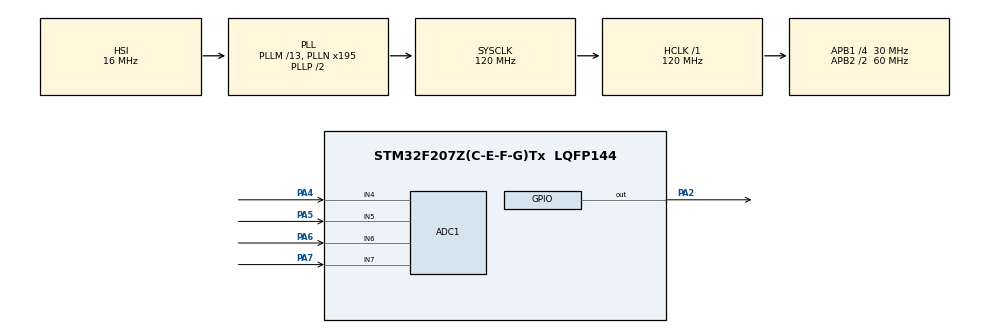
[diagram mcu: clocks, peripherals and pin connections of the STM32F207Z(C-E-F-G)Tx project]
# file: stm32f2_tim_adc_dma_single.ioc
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ADC1.Channel-0\#ChannelRegularConversion=ADC_CHANNEL_4
ADC1.Channel-1\#ChannelRegularConversion=ADC_CHANNEL_5
ADC1.Channel-2\#ChannelRegularConversion=ADC_CHANNEL_6
ADC1.Channel-3\#ChannelRegularConversion=ADC_CHANNEL_7
ADC1.DMAContinuousRequests=ENABLE
ADC1.ExternalTrigConv=ADC_EXTERNALTRIGCONV_T2_TRGO
ADC1.NbrOfConversion=4
ADC1.NbrOfConversionFlag=1
ADC1.Rank-0\#ChannelRegularConversion=1
ADC1.Rank-1\#ChannelRegularConversion=2
ADC1.Rank-2\#ChannelRegularConversion=3
ADC1.Rank-3\#ChannelRegularConversion=4
ADC1.SamplingTime-0\#ChannelRegularConversion=ADC_SAMPLETIME_3CYCLES
ADC1.SamplingTime-1\#ChannelRegularConversion=ADC_SAMPLETIME_3CYCLES
ADC1.SamplingTime-2\#ChannelRegularConversion=ADC_SAMPLETIME_3CYCLES
ADC1.SamplingTime-3\#ChannelRegularConversion=ADC_SAMPLETIME_3CYCLES
ADC1.master=1
Dma.ADC1.0.Direction=DMA_PERIPH_TO_MEMORY
Dma.ADC1.0.FIFOMode=DMA_FIFOMODE_DISABLE
Dma.ADC1.0.Instance=DMA2_Stream0
Dma.ADC1.0.MemDataAlignment=DMA_MDATAALIGN_HALFWORD
Dma.ADC1.0.MemInc=DMA_MINC_ENABLE
Dma.ADC1.0.Mode=DMA_CIRCULAR
Dma.ADC1.0.PeriphDataAlignment=DMA_PDATAALIGN_HALFWORD
Dma.ADC1.0.PeriphInc=DMA_PINC_DISABLE
Dma.ADC1.0.Priority=DMA_PRIORITY_LOW
Dma.Request0=ADC1
Mcu.Family=STM32F2
Mcu.Name=STM32F207Z(C-E-F-G)Tx
Mcu.Package=LQFP144
NVIC.ADC_IRQn=true\:0\:0\:false\:false\:true\:true\:true\:true
NVIC.DMA2_Stream0_IRQn=true\:0\:0\:false\:false\:true\:false\:true\:true
NVIC.PriorityGroup=NVIC_PRIORITYGROUP_4
NVIC.TIM2_IRQn=true\:0\:0\:false\:false\:true\:true\:true\:true
NVIC.TIM3_IRQn=true\:0\:0\:false\:false\:true\:true\:true\:true
PA13.Mode=Serial_Wire
PA13.Signal=SYS_JTMS-SWDIO
PA14.Mode=Serial_Wire
PA14.Signal=SYS_JTCK-SWCLK
PA2.Signal=GPIO_Output
PA4.Signal=ADCx_IN4
PA5.Signal=ADCx_IN5
PA6.Signal=ADCx_IN6
PA7.Signal=ADCx_IN7
PH0-OSC_IN.Mode=HSE-External-Oscillator
PH0-OSC_IN.Signal=RCC_OSC_IN
PH1-OSC_OUT.Mode=HSE-External-Oscillator
PH1-OSC_OUT.Signal=RCC_OSC_OUT
ProjectManager.HeapSize=0x200
ProjectManager.StackSize=0x400
ProjectManager.TargetToolchain=STM32CubeIDE
RCC.48MHZClocksFreq_Value=60000000
RCC.AHBFreq_Value=120000000
RCC.APB1CLKDivider=RCC_HCLK_DIV4
RCC.APB1Freq_Value=30000000
RCC.APB1TimFreq_Value=60000000
RCC.APB2CLKDivider=RCC_HCLK_DIV2
RCC.APB2Freq_Value=60000000
RCC.APB2TimFreq_Value=120000000
RCC.CortexFreq_Value=120000000
RCC.HCLKFreq_Value=120000000
RCC.HSE_VALUE=25000000
RCC.HSI_VALUE=16000000
RCC.LSE_VALUE=32768
RCC.PLLM=13
RCC.PLLN=195
RCC.SYSCLKFreq_VALUE=120000000
RCC.SYSCLKSource=RCC_SYSCLKSOURCE_PLLCLK
RCC.VCOOutputFreq_Value=240000000
SH.ADCx_IN4.0=ADC1_IN4,IN4
SH.ADCx_IN5.0=ADC1_IN5,IN5
SH.ADCx_IN6.0=ADC1_IN6,IN6
SH.ADCx_IN7.0=ADC1_IN7,IN7
TIM2.Channel-PWM\ Generation1\ No\ Output=TIM_CHANNEL_1
TIM2.Period=200-1
TIM2.TIM_MasterOutputTrigger=TIM_TRGO_UPDATE
TIM2.TIM_MasterSlaveMode=TIM_MASTERSLAVEMODE_ENABLE
TIM3.Period=200-1
VP_TIM2_VS_ClockSourceINT.Mode=Internal
VP_TIM2_VS_no_output1.Mode=PWM Generation1 No Output
VP_TIM3_VS_ClockSourceINT.Mode=Internal
board=custom

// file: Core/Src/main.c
/* USER CODE BEGIN Header */
/**
  ******************************************************************************
  * @file           : main.c
  * @brief          : Main program body
  ******************************************************************************
  * @attention
  *
  * Copyright (c) 2023 STMicroelectronics.
  * All rights reserved.
  *
  * This software is licensed under terms that can be found in the LICENSE file
  * in the root directory of this software component.
  * If no LICENSE file comes with this software, it is provided AS-IS.
  *
  ******************************************************************************
  */
/* USER CODE END Header */
#include "main.h"

ADC_HandleTypeDef hadc1;
DMA_HandleTypeDef hdma_adc1;

TIM_HandleTypeDef htim2;
TIM_HandleTypeDef htim3;

/* USER CODE BEGIN PV */
uint16_t adc_values[4];
float Vout[4];
/* USER CODE END PV */

void SystemClock_Config(void);
static void MX_GPIO_Init(void);
static void MX_DMA_Init(void);
static void MX_ADC1_Init(void);
static void MX_TIM2_Init(void);
static void MX_TIM3_Init(void);

int main(void)
{

  /* MCU Configuration--------------------------------------------------------*/

  /* Reset of all peripherals, Initializes the Flash interface and the Systick. */
  HAL_Init();

  /* Configure the system clock */
  SystemClock_Config();

  /* Initialize all configured peripherals */
  MX_GPIO_Init();
  MX_DMA_Init();
  MX_ADC1_Init();
  MX_TIM2_Init();
  MX_TIM3_Init();
  /* USER CODE BEGIN 2 */
  HAL_ADC_Start_DMA(&hadc1, &adc_values, 4);
//  HAL_TIM_Base_Start(&htim2);
//  HAL_TIM_Base_Start_IT(&htim3);
  HAL_TIM_Base_Start(&htim2);

  /* USER CODE END 2 */

  /* Infinite loop */
  while (1)
  {

  }
}

void SystemClock_Config(void)
{
  RCC_OscInitTypeDef RCC_OscInitStruct = {0};
  RCC_ClkInitTypeDef RCC_ClkInitStruct = {0};

  /** Initializes the RCC Oscillators according to the specified parameters
  * in the RCC_OscInitTypeDef structure.
  */
  RCC_OscInitStruct.OscillatorType = RCC_OSCILLATORTYPE_HSI;
  RCC_OscInitStruct.HSIState = RCC_HSI_ON;
  RCC_OscInitStruct.HSICalibrationValue = RCC_HSICALIBRATION_DEFAULT;
  RCC_OscInitStruct.PLL.PLLState = RCC_PLL_ON;
  RCC_OscInitStruct.PLL.PLLSource = RCC_PLLSOURCE_HSI;
  RCC_OscInitStruct.PLL.PLLM = 13;
  RCC_OscInitStruct.PLL.PLLN = 195;
  RCC_OscInitStruct.PLL.PLLP = RCC_PLLP_DIV2;
  RCC_OscInitStruct.PLL.PLLQ = 4;
  if (HAL_RCC_OscConfig(&RCC_OscInitStruct) != HAL_OK)
  {
    Error_Handler();
  }

  /** Initializes the CPU, AHB and APB buses clocks
  */
  RCC_ClkInitStruct.ClockType = RCC_CLOCKTYPE_HCLK|RCC_CLOCKTYPE_SYSCLK
                              |RCC_CLOCKTYPE_PCLK1|RCC_CLOCKTYPE_PCLK2;
  RCC_ClkInitStruct.SYSCLKSource = RCC_SYSCLKSOURCE_PLLCLK;
  RCC_ClkInitStruct.AHBCLKDivider = RCC_SYSCLK_DIV1;
  RCC_ClkInitStruct.APB1CLKDivider = RCC_HCLK_DIV4;
  RCC_ClkInitStruct.APB2CLKDivider = RCC_HCLK_DIV2;

  if (HAL_RCC_ClockConfig(&RCC_ClkInitStruct, FLASH_LATENCY_3) != HAL_OK)
  {
    Error_Handler();
  }
}

static void MX_ADC1_Init(void)
{

  ADC_ChannelConfTypeDef sConfig = {0};

  /** Configure the global features of the ADC (Clock, Resolution, Data Alignment and number of conversion)
  */
  hadc1.Instance = ADC1;
  hadc1.Init.ClockPrescaler = ADC_CLOCK_SYNC_PCLK_DIV2;
  hadc1.Init.Resolution = ADC_RESOLUTION_12B;
  hadc1.Init.ScanConvMode = ENABLE;
  hadc1.Init.ContinuousConvMode = DISABLE;
  hadc1.Init.DiscontinuousConvMode = DISABLE;
  hadc1.Init.ExternalTrigConvEdge = ADC_EXTERNALTRIGCONVEDGE_RISING;
  hadc1.Init.ExternalTrigConv = ADC_EXTERNALTRIGCONV_T2_TRGO;
  hadc1.Init.DataAlign = ADC_DATAALIGN_RIGHT;
  hadc1.Init.NbrOfConversion = 4;
  hadc1.Init.DMAContinuousRequests = ENABLE;
  hadc1.Init.EOCSelection = ADC_EOC_SINGLE_CONV;
  if (HAL_ADC_Init(&hadc1) != HAL_OK)
  {
    Error_Handler();
  }

  /** Configure for the selected ADC regular channel its corresponding rank in the sequencer and its sample time.
  */
  sConfig.Channel = ADC_CHANNEL_4;
  sConfig.Rank = 1;
  sConfig.SamplingTime = ADC_SAMPLETIME_3CYCLES;
  if (HAL_ADC_ConfigChannel(&hadc1, &sConfig) != HAL_OK)
  {
    Error_Handler();
  }

  /** Configure for the selected ADC regular channel its corresponding rank in the sequencer and its sample time.
  */
  sConfig.Channel = ADC_CHANNEL_5;
  sConfig.Rank = 2;
  if (HAL_ADC_ConfigChannel(&hadc1, &sConfig) != HAL_OK)
  {
    Error_Handler();
  }

  /** Configure for the selected ADC regular channel its corresponding rank in the sequencer and its sample time.
  */
  sConfig.Channel = ADC_CHANNEL_6;
  sConfig.Rank = 3;
  if (HAL_ADC_ConfigChannel(&hadc1, &sConfig) != HAL_OK)
  {
    Error_Handler();
  }

  /** Configure for the selected ADC regular channel its corresponding rank in the sequencer and its sample time.
  */
  sConfig.Channel = ADC_CHANNEL_7;
  sConfig.Rank = 4;
  if (HAL_ADC_ConfigChannel(&hadc1, &sConfig) != HAL_OK)
  {
    Error_Handler();
  }

}

static void MX_TIM2_Init(void)
{

  TIM_ClockConfigTypeDef sClockSourceConfig = {0};
  TIM_MasterConfigTypeDef sMasterConfig = {0};
  TIM_OC_InitTypeDef sConfigOC = {0};

  htim2.Instance = TIM2;
  htim2.Init.Prescaler = 0;
  htim2.Init.CounterMode = TIM_COUNTERMODE_UP;
  htim2.Init.Period = 200-1;
  htim2.Init.ClockDivision = TIM_CLOCKDIVISION_DIV1;
  htim2.Init.AutoReloadPreload = TIM_AUTORELOAD_PRELOAD_DISABLE;
  if (HAL_TIM_Base_Init(&htim2) != HAL_OK)
  {
    Error_Handler();
  }
  sClockSourceConfig.ClockSource = TIM_CLOCKSOURCE_INTERNAL;
  if (HAL_TIM_ConfigClockSource(&htim2, &sClockSourceConfig) != HAL_OK)
  {
    Error_Handler();
  }
  if (HAL_TIM_PWM_Init(&htim2) != HAL_OK)
  {
    Error_Handler();
  }
  sMasterConfig.MasterOutputTrigger = TIM_TRGO_UPDATE;
  sMasterConfig.MasterSlaveMode = TIM_MASTERSLAVEMODE_ENABLE;
  if (HAL_TIMEx_MasterConfigSynchronization(&htim2, &sMasterConfig) != HAL_OK)
  {
    Error_Handler();
  }
  sConfigOC.OCMode = TIM_OCMODE_PWM1;
  sConfigOC.Pulse = 0;
  sConfigOC.OCPolarity = TIM_OCPOLARITY_HIGH;
  sConfigOC.OCFastMode = TIM_OCFAST_DISABLE;
  if (HAL_TIM_PWM_ConfigChannel(&htim2, &sConfigOC, TIM_CHANNEL_1) != HAL_OK)
  {
    Error_Handler();
  }

}

static void MX_TIM3_Init(void)
{

  TIM_ClockConfigTypeDef sClockSourceConfig = {0};
  TIM_MasterConfigTypeDef sMasterConfig = {0};

  htim3.Instance = TIM3;
  htim3.Init.Prescaler = 0;
  htim3.Init.CounterMode = TIM_COUNTERMODE_UP;
  htim3.Init.Period = 200-1;
  htim3.Init.ClockDivision = TIM_CLOCKDIVISION_DIV1;
  htim3.Init.AutoReloadPreload = TIM_AUTORELOAD_PRELOAD_DISABLE;
  if (HAL_TIM_Base_Init(&htim3) != HAL_OK)
  {
    Error_Handler();
  }
  sClockSourceConfig.ClockSource = TIM_CLOCKSOURCE_INTERNAL;
  if (HAL_TIM_ConfigClockSource(&htim3, &sClockSourceConfig) != HAL_OK)
  {
    Error_Handler();
  }
  sMasterConfig.MasterOutputTrigger = TIM_TRGO_RESET;
  sMasterConfig.MasterSlaveMode = TIM_MASTERSLAVEMODE_DISABLE;
  if (HAL_TIMEx_MasterConfigSynchronization(&htim3, &sMasterConfig) != HAL_OK)
  {
    Error_Handler();
  }

}

static void MX_DMA_Init(void)
{

  /* DMA controller clock enable */
  __HAL_RCC_DMA2_CLK_ENABLE();

  /* DMA interrupt init */
  /* DMA2_Stream0_IRQn interrupt configuration */
  HAL_NVIC_SetPriority(DMA2_Stream0_IRQn, 0, 0);
  HAL_NVIC_EnableIRQ(DMA2_Stream0_IRQn);

}

static void MX_GPIO_Init(void)
{
  GPIO_InitTypeDef GPIO_InitStruct = {0};

  /* GPIO Ports Clock Enable */
  __HAL_RCC_GPIOH_CLK_ENABLE();
  __HAL_RCC_GPIOA_CLK_ENABLE();

  /*Configure GPIO pin Output Level */
  HAL_GPIO_WritePin(GPIOA, GPIO_PIN_2, GPIO_PIN_RESET);

  /*Configure GPIO pin : PA2 */
  GPIO_InitStruct.Pin = GPIO_PIN_2;
  GPIO_InitStruct.Mode = GPIO_MODE_OUTPUT_PP;
  GPIO_InitStruct.Pull = GPIO_NOPULL;
  GPIO_InitStruct.Speed = GPIO_SPEED_FREQ_LOW;
  HAL_GPIO_Init(GPIOA, &GPIO_InitStruct);

}

/* USER CODE BEGIN 4 */
void HAL_ADC_ConvCpltCallback(ADC_HandleTypeDef* hadc)
{

	HAL_GPIO_TogglePin(GPIOA, GPIO_PIN_2);
	for(int i=0;i<4;i++)
	{
		Vout[i]= adc_values[i] ;
	}

}

//void HAL_TIM_PeriodElapsedCallback(TIM_HandleTypeDef *htim)
//{
//
//
//
//		for(int i=0;i<4;i++)
//		{
//			Vout[i]= adc_values[i];
//		}
//}
/* USER CODE END 4 */

void Error_Handler(void)
{
  __disable_irq();
  while (1)
  {
  }
}
